AUTOSAR XML (schema 4-2-1)
package /COM/VECTOR/CFG/WORKFLOW/SYSDESC/SYNC
  system SYSTEM
    system mapping MAPPINGS
      data-mappings:
        data-element=COMPOSITIONTYPE.PpSteeringWheelPosition.DeSteeringWheelPosition, system-signal=sig_SteeringWheelPosition
        data-element=CpSaRightFrontlight.COMPOSITIONTYPE.PpLightPositionOut.DeLightPosition, system-signal=sig_RightHAngle
        data-element=CpSaLeftFrontlight.COMPOSITIONTYPE.PpLightPositionOut.DeLightPosition, system-signal=sig_LeftHAngle
        data-element=COMPOSITIONTYPE.PpRightLightPositionOut.DeLightPosition, system-signal=sig_RightHAngle
        data-element=COMPOSITIONTYPE.PpLeftLightPositionOut.DeLightPosition, system-signal=sig_LeftHAngle
        data-element=COMPOSITIONTYPE.PpLeftLightPositionOut.DeLightLength, system-signal=sig_LeftLightLength
        data-element=COMPOSITIONTYPE.PpRightLightPositionOut.DeLightLength, system-signal=sig_RightLightLength
        data-element=COMPOSITIONTYPE.PpAmbientLightBrightnessIn.DeAmbientLightBrightness, system-signal=sig_AmbientLightBrightness
        data-element=COMPOSITIONTYPE.PpSpeedometerValueIn.DeSpeedometerValue, system-signal=sig_CurrentSpeedSlider
    root-software-compositions:
      root sw composition prototype COMPOSITIONTYPE: flat-map=FLATMAP, software-composition=COMPOSITIONTYPE
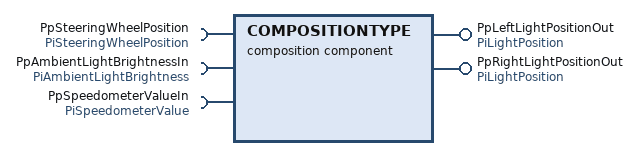
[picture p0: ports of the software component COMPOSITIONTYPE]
  composition sw component type COMPOSITIONTYPE
    require port PpSteeringWheelPosition: nonqueued-receiver-com-spec{data-element=DeSteeringWheelPosition, filter=data-filter-type=ALWAYS, init-value=constant-reference=CSteeringWheelInitPosition}, required-interface=PiSteeringWheelPosition
    provide port PpLeftLightPositionOut: provided-com-specs=[data-element=DeLightLength, {data-element=DeLightPosition, init-value=0}], provided-interface=PiLightPosition
    provide port PpRightLightPositionOut: provided-com-specs=[data-element=DeLightLength, {data-element=DeLightPosition, init-value=0}], provided-interface=PiLightPosition
    require port PpAmbientLightBrightnessIn: nonqueued-receiver-com-spec{data-element=DeAmbientLightBrightness, filter=data-filter-type=ALWAYS, init-value=constant-reference=CDarkLight}, required-interface=PiAmbientLightBrightness
    require port PpSpeedometerValueIn: nonqueued-receiver-com-spec{data-element=DeSpeedometerValue, filter=data-filter-type=ALWAYS, init-value=constant-reference=CInitSpeed}, required-interface=PiSpeedometerValue
    15 x component:
      Dem: type=Dem
      Det: type=Det
      EcuM: type=EcuM
      NvM: type=NvM
      ComM: type=ComM
      BswM: type=BswM
      Dcm: type=Dcm
      CpSaSteeringWheel: type=CtSaSteeringWheel
      CpSaLeftFrontlight: type=CtSaFrontlight
      CpCddIoHwAb: type=CtCddIoHwAb
      CpApAFSController: type=CtApAFSController
      CpSaRightFrontlight: type=CtSaFrontlight
      CpSaSpeedometer: type=CtSaSpeedometer
      CpSaAmbientLight: type=CtSaAmbientLight
      CpApBatteryManager: type=CtApBatteryManager
    connect BswM.Switch_ESH_ModeSwitch -> BswM.Notification_ESH_ModeNotification
    connect CpApAFSController.PpLightPositionLeft -> CpSaLeftFrontlight.PpLightPositionIn
    connect CpApAFSController.PpLightPositionRight -> CpSaRightFrontlight.PpLightPositionIn
    delegate CpSaSteeringWheel.PpSteeringWheelPositionIn <-> outer port PpSteeringWheelPosition
    delegate CpSaRightFrontlight.PpLightPositionOut <-> outer port PpRightLightPositionOut
    delegate CpSaLeftFrontlight.PpLightPositionOut <-> outer port PpLeftLightPositionOut
    connect CpSaSteeringWheel.PpSteeringWheelPositionOut -> CpApAFSController.PpSteeringWheelPosition
    connect CpCddIoHwAb.PpAFSSwitch -> CpApAFSController.PpAFSSwitch
    connect CpCddIoHwAb.PpHighBeam -> CpApAFSController.PpHighBeam
    connect CpApAFSController.DataServices_Diag_RDI_BatteryValue_BatteryValue -> Dcm.DataServices_Diag_RDI_BatteryValue_BatteryValue
    connect CpApAFSController.DataServices_Diag_RWDI_PassingLane_PassingLane_PassingLane -> Dcm.DataServices_Diag_RWDI_PassingLane_PassingLane_PassingLane
    connect CpSaAmbientLight.PpAmbientLightBrightnessOut -> CpApAFSController.PpAmbientLightBrightnessIn
    connect CpSaSpeedometer.PpSpeedometerValueOut -> CpApAFSController.PpSpeedometerValueIn
    delegate CpSaSpeedometer.PpSpeedometerValueIn <-> outer port PpSpeedometerValueIn
    delegate CpSaAmbientLight.PpAmbientLightBrightnessIn <-> outer port PpAmbientLightBrightnessIn
    connect CpCddIoHwAb.PpBatterLevel -> CpApBatteryManager.PpBatterLevelIn
    connect CpApBatteryManager.PpBswMBatteryLevel -> BswM.Notification_SWC_MODE_NOTIFICATION_BswM_MDGP_MdgBswMBatteryModes
    connect CpApBatteryManager.PpBatteryMode -> CpApAFSController.PpBatterModeIn
    connect CpApAFSController.PpBatteryModeOut -> CpSaAmbientLight.PpBatterModeIn
    connect CpApAFSController.PpBatteryModeOut -> CpSaSpeedometer.PpBatterModeIn
    connect CpApAFSController.PpBatteryModeOut -> CpSaSteeringWheel.PpBatterModeIn
    connect Dem.Event_DTC_0x000002 -> CpApBatteryManager.Event_DTC_0x000002
  end to end protection set E2EPROTECTIONSET
  port interface mapping set PORTINTERFACEMAPPINGSET
